# PIC32MZ2048EFM144 register map
Registers are 32-bit, access not given, reset 0x0 unless marked. A register's access mark holds for its fields unless they carry their own. Offsets are from the block's base; [hi:lo] are bit positions; {n}, {i} and the like mark numbered series; 'fields as' and 'values as' point back to an identical list.

## PCACHE — PCACHE peripheral
Base 0xBF8E0000
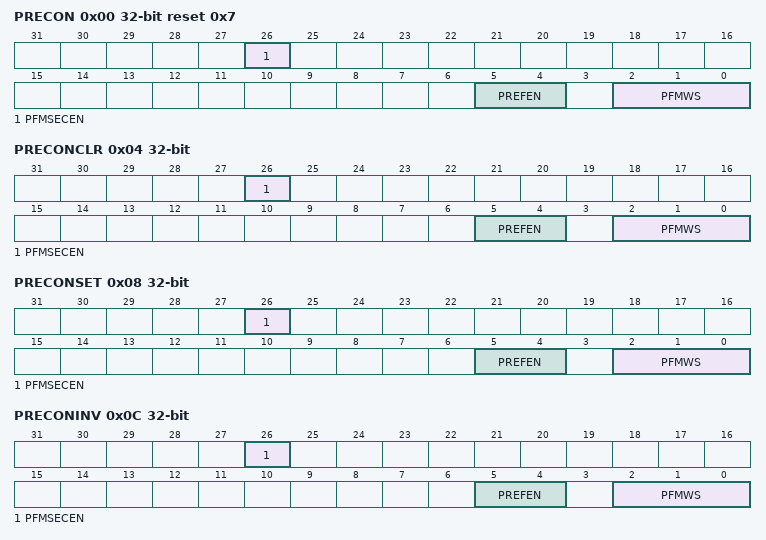
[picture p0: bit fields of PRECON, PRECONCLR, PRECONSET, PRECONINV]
0x00 PRECON reset 0x7
  [26] PFMSECEN, [5:4] PREFEN, [2:0] PFMWS
0x04 PRECONCLR
  [26] PFMSECEN, [5:4] PREFEN, [2:0] PFMWS
0x08 PRECONSET
  [26] PFMSECEN, [5:4] PREFEN, [2:0] PFMWS
0x0C PRECONINV
  [26] PFMSECEN, [5:4] PREFEN, [2:0] PFMWS
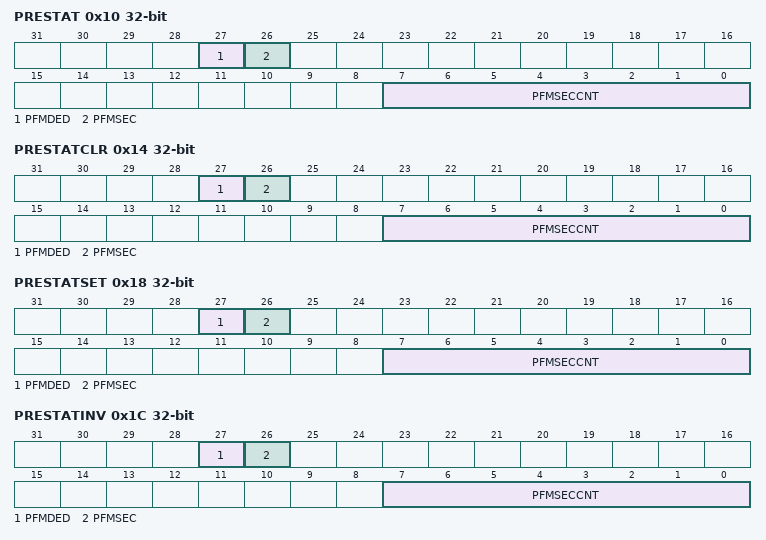
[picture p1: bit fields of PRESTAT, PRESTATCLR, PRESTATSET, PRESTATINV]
0x10 PRESTAT
  [27] PFMDED, [26] PFMSEC, [7:0] PFMSECCNT
0x14 PRESTATCLR
  [27] PFMDED, [26] PFMSEC, [7:0] PFMSECCNT
0x18 PRESTATSET
  [27] PFMDED, [26] PFMSEC, [7:0] PFMSECCNT
0x1C PRESTATINV
  [27] PFMDED, [26] PFMSEC, [7:0] PFMSECCNT

## EBI — EBI peripheral
Base 0xBF8E1014
{0x0+4i} EBICS{i} (i=0..3)
  [31:16] CSADDR
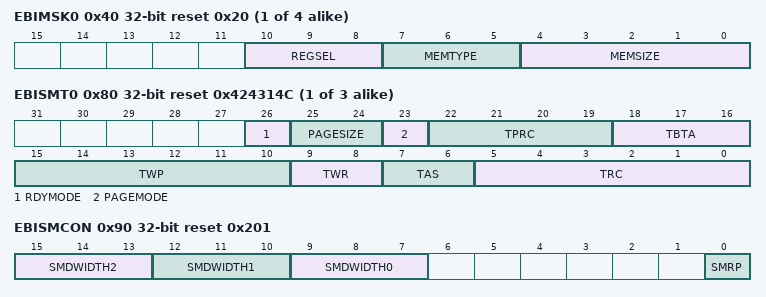
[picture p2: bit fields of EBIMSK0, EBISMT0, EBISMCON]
{0x40+4i} EBIMSK{i} reset 0x20 (i=0..3)
  [10:8] REGSEL, [7:5] MEMTYPE, [4:0] MEMSIZE
{0x80+4i} EBISMT{i} reset 0x424314C (i=0..2)
  [26] RDYMODE, [25:24] PAGESIZE, [23] PAGEMODE, [22:19] TPRC, [18:16] TBTA, [15:10] TWP, [9:8] TWR, [7:6] TAS, [5:0] TRC
0x8C EBIFTRPD reset 0x201
  [31:0] TRPD
0x90 EBISMCON reset 0x201
  [15:13] SMDWIDTH2, [12:10] SMDWIDTH1, [9:7] SMDWIDTH0, [0] SMRP

## SQI1 — SQI1 peripheral
Base 0xBF8E2000
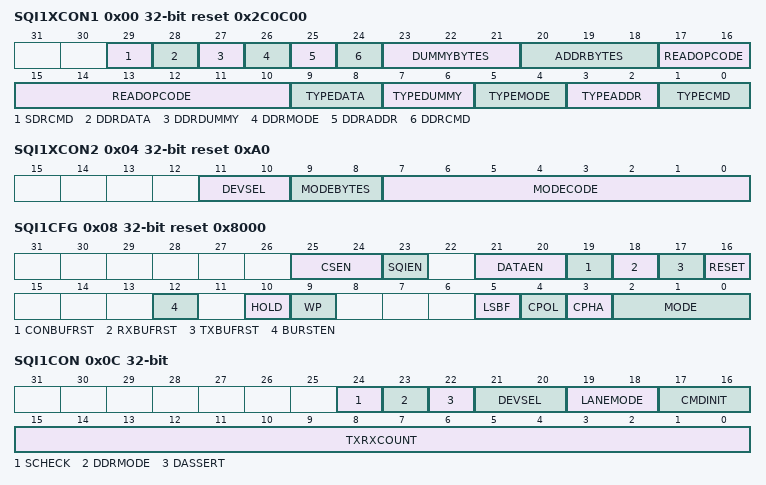
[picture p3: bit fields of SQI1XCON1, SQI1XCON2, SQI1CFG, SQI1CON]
0x00 SQI1XCON1 reset 0x2C0C00
  [29] SDRCMD, [28] DDRDATA, [27] DDRDUMMY, [26] DDRMODE, [25] DDRADDR, [24] DDRCMD, [23:21] DUMMYBYTES, [20:18] ADDRBYTES, [17:10] READOPCODE, [9:8] TYPEDATA, [7:6] TYPEDUMMY, [5:4] TYPEMODE, [3:2] TYPEADDR, [1:0] TYPECMD
0x04 SQI1XCON2 reset 0xA0
  [11:10] DEVSEL, [9:8] MODEBYTES, [7:0] MODECODE
0x08 SQI1CFG reset 0x8000
  [25:24] CSEN, [23] SQIEN, [21:20] DATAEN, [19] CONBUFRST, [18] RXBUFRST, [17] TXBUFRST, [16] RESET, [12] BURSTEN, [10] HOLD, [9] WP, [5] LSBF, [4] CPOL, [3] CPHA, [2:0] MODE
0x0C SQI1CON
  [24] SCHECK, [23] DDRMODE, [22] DASSERT, [21:20] DEVSEL, [19:18] LANEMODE, [17:16] CMDINIT, [15:0] TXRXCOUNT
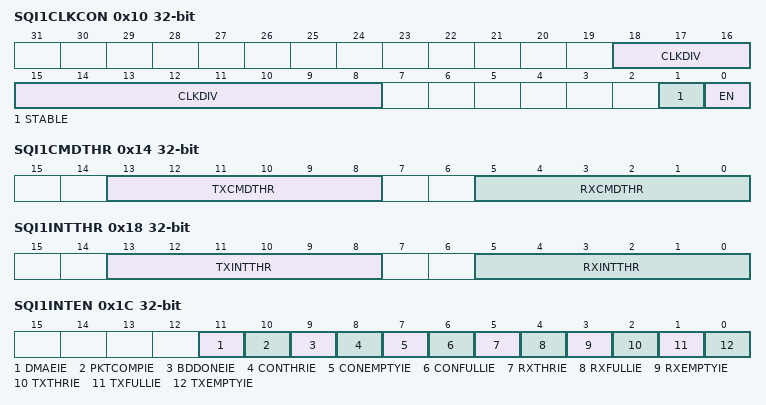
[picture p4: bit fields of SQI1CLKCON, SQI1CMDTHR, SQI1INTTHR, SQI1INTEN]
0x10 SQI1CLKCON
  [18:8] CLKDIV, [1] STABLE, [0] EN
0x14 SQI1CMDTHR
  [13:8] TXCMDTHR, [5:0] RXCMDTHR
0x18 SQI1INTTHR
  [13:8] TXINTTHR, [5:0] RXINTTHR
0x1C SQI1INTEN
  [11] DMAEIE, [10] PKTCOMPIE, [9] BDDONEIE, [8] CONTHRIE, [7] CONEMPTYIE, [6] CONFULLIE, [5] RXTHRIE, [4] RXFULLIE, [3] RXEMPTYIE, [2] TXTHRIE, [1] TXFULLIE, [0] TXEMPTYIE
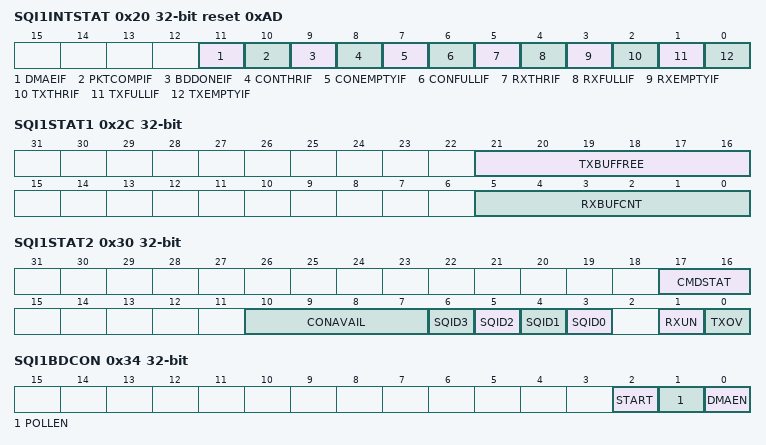
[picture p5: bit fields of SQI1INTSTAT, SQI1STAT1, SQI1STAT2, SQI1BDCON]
0x20 SQI1INTSTAT reset 0xAD
  [11] DMAEIF, [10] PKTCOMPIF, [9] BDDONEIF, [8] CONTHRIF, [7] CONEMPTYIF, [6] CONFULLIF, [5] RXTHRIF, [4] RXFULLIF, [3] RXEMPTYIF, [2] TXTHRIF, [1] TXFULLIF, [0] TXEMPTYIF
0x24 SQI1TXDATA
  [31:0] TXDATA
0x28 SQI1RXDATA
  [31:0] RXDATA
0x2C SQI1STAT1
  [21:16] TXBUFFREE, [5:0] RXBUFCNT
0x30 SQI1STAT2
  [17:16] CMDSTAT, [10:7] CONAVAIL, [n+3] SQID{n} (n=0..3), [1] RXUN, [0] TXOV
0x34 SQI1BDCON
  [2] START, [1] POLLEN, [0] DMAEN
0x38 SQI1BDCURADD
  [31:0] BDCURRADDR
0x40 SQI1BDBASEADD
  [31:0] BDADDR
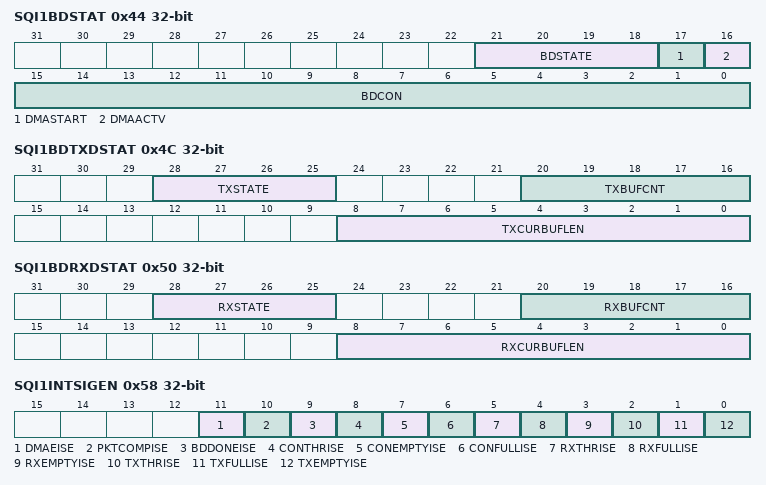
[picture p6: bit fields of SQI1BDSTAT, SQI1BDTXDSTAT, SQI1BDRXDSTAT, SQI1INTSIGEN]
0x44 SQI1BDSTAT
  [21:18] BDSTATE, [17] DMASTART, [16] DMAACTV, [15:0] BDCON
0x48 SQI1BDPOLLCON
  [15:0] POLLCON
0x4C SQI1BDTXDSTAT
  [28:25] TXSTATE, [20:16] TXBUFCNT, [8:0] TXCURBUFLEN
0x50 SQI1BDRXDSTAT
  [28:25] RXSTATE, [20:16] RXBUFCNT, [8:0] RXCURBUFLEN
0x54 SQI1THR
  [3:0] THRES
0x58 SQI1INTSIGEN
  [11] DMAEISE, [10] PKTCOMPISE, [9] BDDONEISE, [8] CONTHRISE, [7] CONEMPTYISE, [6] CONFULLISE, [5] RXTHRISE, [4] RXFULLISE, [3] RXEMPTYISE, [2] TXTHRISE, [1] TXFULLISE, [0] TXEMPTYISE
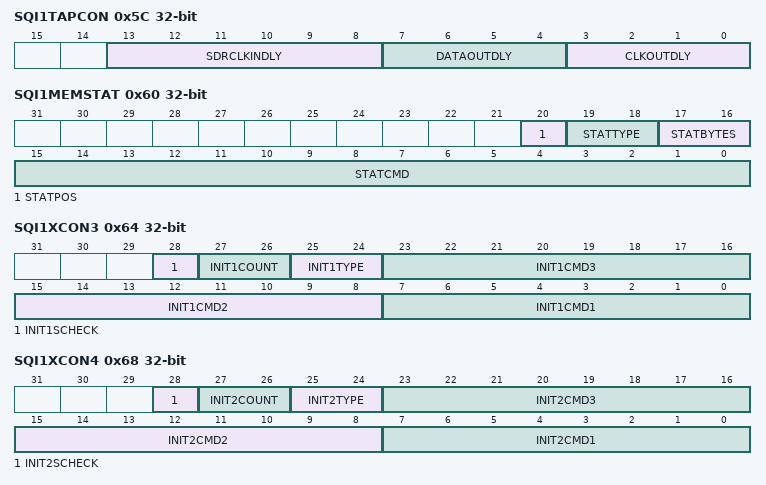
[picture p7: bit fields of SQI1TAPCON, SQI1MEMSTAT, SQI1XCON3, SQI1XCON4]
0x5C SQI1TAPCON
  [13:8] SDRCLKINDLY, [7:4] DATAOUTDLY, [3:0] CLKOUTDLY
0x60 SQI1MEMSTAT
  [20] STATPOS, [19:18] STATTYPE, [17:16] STATBYTES, [15:0] STATCMD
0x64 SQI1XCON3
  [28] INIT1SCHECK, [27:26] INIT1COUNT, [25:24] INIT1TYPE, [23:16] INIT1CMD3, [15:8] INIT1CMD2, [7:0] INIT1CMD1
0x68 SQI1XCON4
  [28] INIT2SCHECK, [27:26] INIT2COUNT, [25:24] INIT2TYPE, [23:16] INIT2CMD3, [15:8] INIT2CMD2, [7:0] INIT2CMD1

## USB — USB peripheral
Base 0xBF8E3000
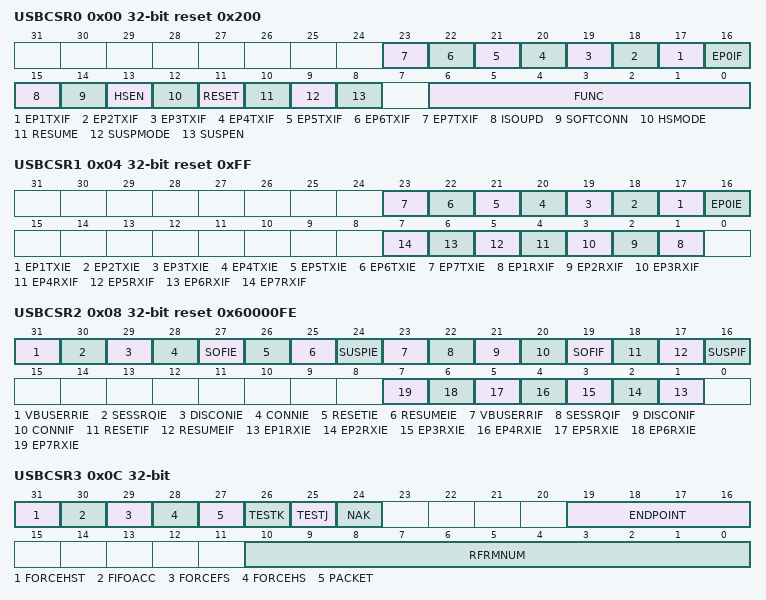
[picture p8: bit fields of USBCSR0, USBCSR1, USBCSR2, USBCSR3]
0x00 USBCSR0 reset 0x200
  [n+16] EP{n}TXIF (n=1..7), [16] EP0IF, [15] ISOUPD, [14] SOFTCONN, [13] HSEN, [12] HSMODE, [11] RESET, [10] RESUME, [9] SUSPMODE, [8] SUSPEN, [6:0] FUNC
0x04 USBCSR1 reset 0xFF
  [n+16] EP{n}TXIE (n=1..7), [16] EP0IE, [n] EP{n}RXIF (n=1..7)
0x08 USBCSR2 reset 0x60000FE
  [31] VBUSERRIE, [30] SESSRQIE, [29] DISCONIE, [28] CONNIE, [27] SOFIE, [26] RESETIE, [25] RESUMEIE, [24] SUSPIE, [23] VBUSERRIF, [22] SESSRQIF, [21] DISCONIF, [20] CONNIF, [19] SOFIF, [18] RESETIF, [17] RESUMEIF, [16] SUSPIF, [n] EP{n}RXIE (n=1..7)
0x0C USBCSR3
  [31] FORCEHST, [30] FIFOACC, [29] FORCEFS, [28] FORCEHS, [27] PACKET, [26] TESTK, [25] TESTJ, [24] NAK, [19:16] ENDPOINT, [10:0] RFRMNUM
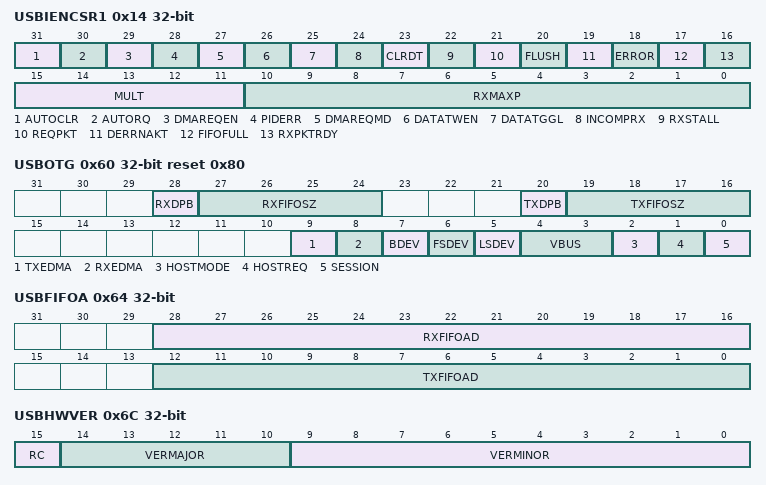
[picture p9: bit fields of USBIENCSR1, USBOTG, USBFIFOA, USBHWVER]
0x14 USBIENCSR1
  [31] AUTOCLR, [30] AUTORQ, [29] DMAREQEN, [28] PIDERR, [27] DMAREQMD, [26] DATATWEN, [25] DATATGGL, [24] INCOMPRX, [23] CLRDT, [22] RXSTALL, [21] REQPKT, [20] FLUSH, [19] DERRNAKT, [18] ERROR, [17] FIFOFULL, [16] RXPKTRDY, [15:11] MULT, [10:0] RXMAXP
{0x20+4i} USBFIFO{i} (i=0..7)
  [31:0] DATA
0x60 USBOTG reset 0x80
  [28] RXDPB, [27:24] RXFIFOSZ, [20] TXDPB, [19:16] TXFIFOSZ, [9] TXEDMA, [8] RXEDMA, [7] BDEV, [6] FSDEV, [5] LSDEV, [4:3] VBUS, [2] HOSTMODE, [1] HOSTREQ, [0] SESSION
0x64 USBFIFOA
  [28:16] RXFIFOAD, [12:0] TXFIFOAD
0x6C USBHWVER
  [15] RC, [14:10] VERMAJOR, [9:0] VERMINOR
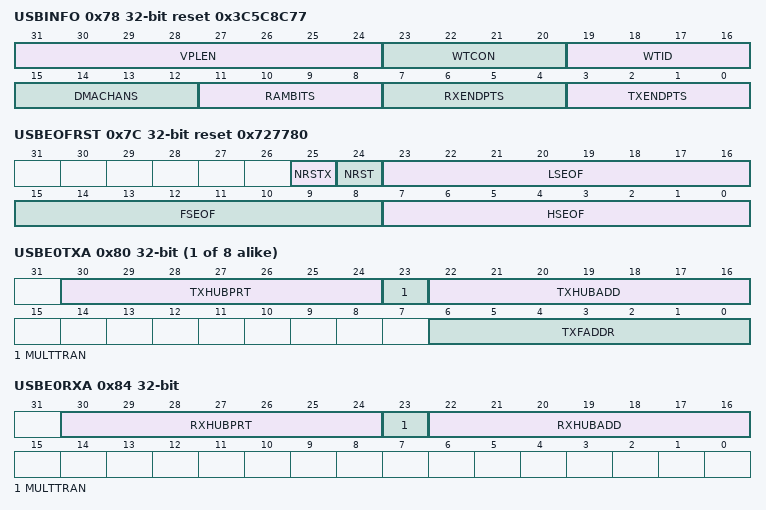
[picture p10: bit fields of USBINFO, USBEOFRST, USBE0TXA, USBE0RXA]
0x78 USBINFO reset 0x3C5C8C77
  [31:24] VPLEN, [23:20] WTCON, [19:16] WTID, [15:12] DMACHANS, [11:8] RAMBITS, [7:4] RXENDPTS, [3:0] TXENDPTS
0x7C USBEOFRST reset 0x727780
  [25] NRSTX, [24] NRST, [23:16] LSEOF, [15:8] FSEOF, [7:0] HSEOF
{0x80+8i} USBE{i}TXA (i=0..7)
  [30:24] TXHUBPRT, [23] MULTTRAN, [22:16] TXHUBADD, [6:0] TXFADDR
0x84 USBE0RXA
  [30:24] RXHUBPRT, [23] MULTTRAN, [22:16] RXHUBADD
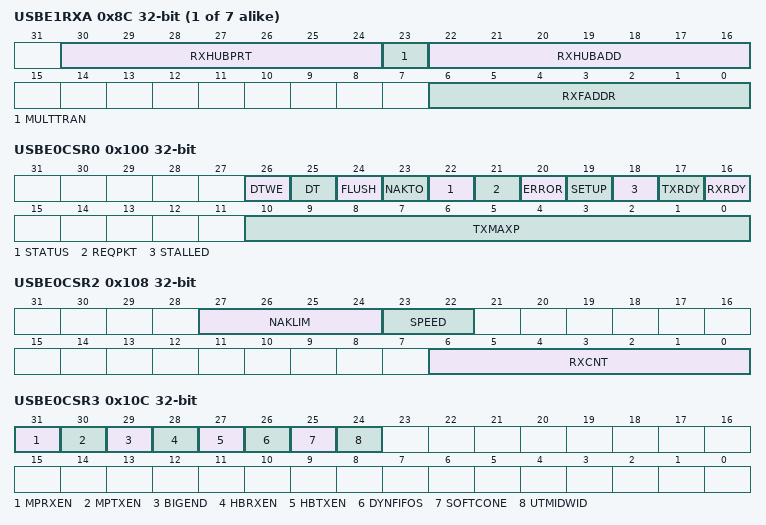
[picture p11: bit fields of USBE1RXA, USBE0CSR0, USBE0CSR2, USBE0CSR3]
{0x84+8i} USBE{i}RXA (i=1..7)
  [30:24] RXHUBPRT, [23] MULTTRAN, [22:16] RXHUBADD, [6:0] RXFADDR
0x100 USBE0CSR0
  [26] DTWE, [25] DT, [24] FLUSH, [23] NAKTO, [22] STATUS, [21] REQPKT, [20] ERROR, [19] SETUP, [18] STALLED, [17] TXRDY, [16] RXRDY, [10:0] TXMAXP
0x108 USBE0CSR2
  [27:24] NAKLIM, [23:22] SPEED, [6:0] RXCNT
0x10C USBE0CSR3
  [31] MPRXEN, [30] MPTXEN, [29] BIGEND, [28] HBRXEN, [27] HBTXEN, [26] DYNFIFOS, [25] SOFTCONE, [24] UTMIDWID
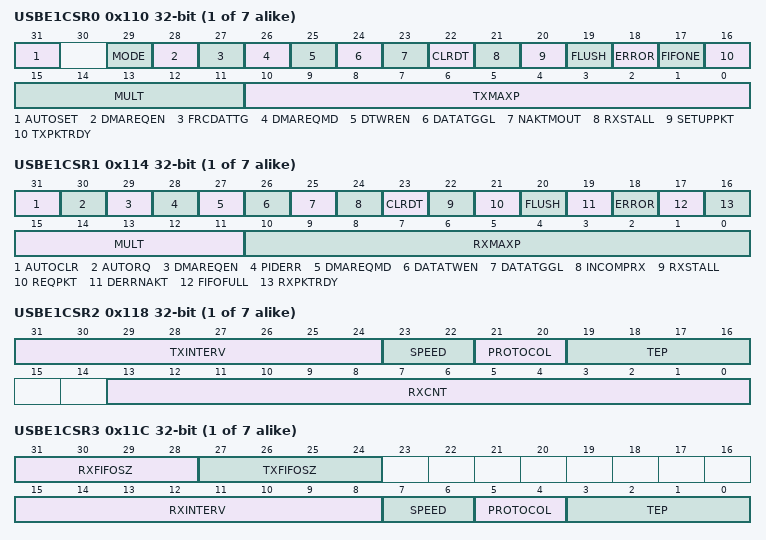
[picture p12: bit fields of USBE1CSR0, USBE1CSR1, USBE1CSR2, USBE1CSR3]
{0x100+0x10*i} USBE{i}CSR0 (i=1..7)
  [31] AUTOSET, [29] MODE, [28] DMAREQEN, [27] FRCDATTG, [26] DMAREQMD, [25] DTWREN, [24] DATATGGL, [23] NAKTMOUT, [22] CLRDT, [21] RXSTALL, [20] SETUPPKT, [19] FLUSH, [18] ERROR, [17] FIFONE, [16] TXPKTRDY, [15:11] MULT, [10:0] TXMAXP
{0x104+0x10*i} USBE{i}CSR1 (i=1..7)
  fields as USBIENCSR1
{0x108+0x10*i} USBE{i}CSR2 (i=1..7)
  [31:24] TXINTERV, [23:22] SPEED, [21:20] PROTOCOL, [19:16] TEP, [13:0] RXCNT
{0x10C+0x10*i} USBE{i}CSR3 (i=1..7)
  [31:28] RXFIFOSZ, [27:24] TXFIFOSZ, [15:8] RXINTERV, [7:6] SPEED, [5:4] PROTOCOL, [3:0] TEP
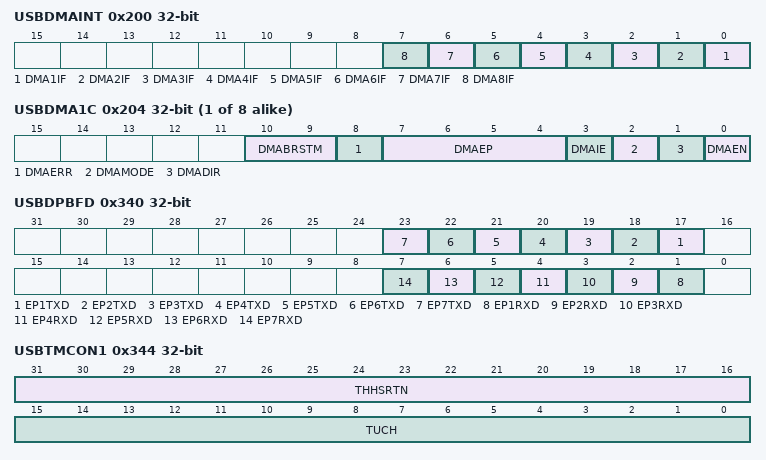
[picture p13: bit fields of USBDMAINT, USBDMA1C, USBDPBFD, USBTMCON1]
0x200 USBDMAINT
  [n-1] DMA{n}IF (n=1..8)
{0x1F4+0x10*i} USBDMA{i}C (i=1..8)
  [10:9] DMABRSTM, [8] DMAERR, [7:4] DMAEP, [3] DMAIE, [2] DMAMODE, [1] DMADIR, [0] DMAEN
{0x1F8+0x10*i} USBDMA{i}A (i=1..8)
  [31:0] DMAADDR
{0x1FC+0x10*i} USBDMA{i}N (i=1..8)
  [31:0] DMACOUNT
{0x300+4i} USBE{i}RPC (i=1..7)
  [15:0] RQPKTCNT
0x340 USBDPBFD
  [n+16] EP{n}TXD (n=1..7), [n] EP{n}RXD (n=1..7)
0x344 USBTMCON1
  [31:16] THHSRTN, [15:0] TUCH
0x348 USBTMCON2
  [3:0] THSBT
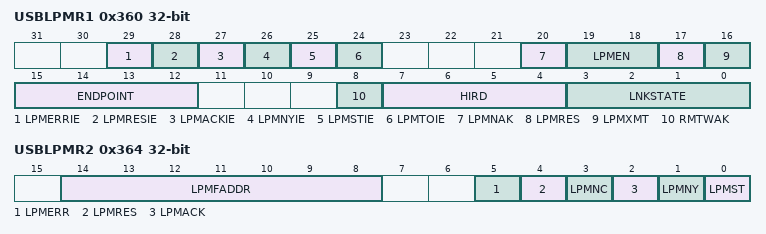
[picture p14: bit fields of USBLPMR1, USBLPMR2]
0x360 USBLPMR1
  [29] LPMERRIE, [28] LPMRESIE, [27] LPMACKIE, [26] LPMNYIE, [25] LPMSTIE, [24] LPMTOIE, [20] LPMNAK, [19:18] LPMEN, [17] LPMRES, [16] LPMXMT, [15:12] ENDPOINT, [8] RMTWAK, [7:4] HIRD, [3:0] LNKSTATE
0x364 USBLPMR2
  [14:8] LPMFADDR, [5] LPMERR, [4] LPMRES, [3] LPMNC, [2] LPMACK, [1] LPMNY, [0] LPMST

## CRYPTO — CRYPTO peripheral
Base 0xBF8E5000
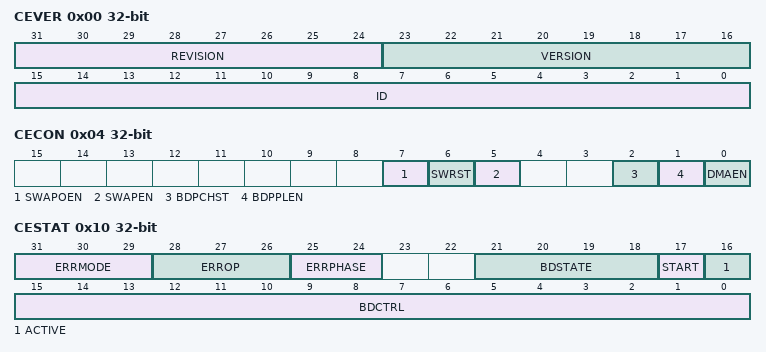
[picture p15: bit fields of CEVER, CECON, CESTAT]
0x00 CEVER
  [31:24] REVISION, [23:16] VERSION, [15:0] ID
0x04 CECON
  [7] SWAPOEN, [6] SWRST, [5] SWAPEN, [2] BDPCHST, [1] BDPPLEN, [0] DMAEN
0x08 CEBDADDR
  [31:0] BDPADDR
0x0C CEBDPADDR
  [31:0] BASEADDR
0x10 CESTAT
  [31:29] ERRMODE, [28:26] ERROP, [25:24] ERRPHASE, [21:18] BDSTATE, [17] START, [16] ACTIVE, [15:0] BDCTRL
0x14 CEINTSRC
  [3] AREIF, [2] PKTIF, [1] CBDIF, [0] PENDIF
0x18 CEINTEN
  [3] AREIE, [2] PKTIE, [1] CBDIE, [0] PENDIE
0x1C CEPOLLCON
  [15:0] BDPPLCON
0x20 CEHDLEN
  [7:0] HDRLEN
0x24 CETRLLEN
  [7:0] TRLRLEN

## RNG — RNG peripheral
Base 0xBF8E6000
0x00 RNGVER
  [31:16] ID, [15:7] VERSION, [6:0] REVISION
0x04 RNGCON reset 0x40
  [12] LOAD, [11] TRNGMODE, [10] CONT, [9] PRNGEN, [8] TRNGEN, [7:0] PLEN
0x08 RNGPOLY1 reset 0xFFFF0000
  [31:0] POLY
0x0C RNGPOLY2 reset 0xFFFF0000
  [31:0] POLY
0x10 RNGNUMGEN1 reset 0xFFFFFFFF
  [31:0] RNG
0x14 RNGNUMGEN2 reset 0xFFFFFFFF
  [31:0] RNG
0x18 RNGSEED1
  [31:0] SEED
0x1C RNGSEED2
  [31:0] SEED
0x20 RNGCNT
  [6:0] RCNT

## SB — SB peripheral
Base 0xBF8F0510
0x00 SBFLAG
  [n] T{n}PGV (n=0..13)
{0x7B10+0x400*i} SBT{i}ELOG1 (i=0..13)
  [31] MULTI, [27:24] CODE, [15:8] INITID, [7:4] REGION, [2:0] CMD
{0x7B14+0x400*i} SBT{i}ELOG2 (i=0..13)
  [1:0] GROUP
{0x7B18+0x400*i} SBT{i}ECON (i=0..13)
  [24] ERRP
{0x7B20+0x400*i} SBT{i}ECLRS (i=0..13)
  [0] CLEAR
{0x7B28+0x400*i} SBT{i}ECLRM (i=0..13)
  [0] CLEAR
{0x7B30+0x400*i} SBT{i}REG0 (i=0..13)
  [31:10] BASE, [9] PRI, [7:3] SIZE
{0x7B40+0x400*i} SBT{i}RD0 reset 0xF (i=0..13)
  [n] GROUP{n} (n=0..3)
{0x7B48+0x400*i} SBT{i}WR0 reset 0xF (i=0..13)
  [n] GROUP{n} (n=0..3)
0x7B50 SBT0REG1
  [31:10] BASE, [9] PRI, [7:3] SIZE
0x7B60 SBT0RD1 reset 0xF
  [n] GROUP{n} (n=0..3)
0x7B68 SBT0WR1 reset 0xF
  [n] GROUP{n} (n=0..3)
{0x7B70+0x400*i} SBT{i}REG2 (i=1..5)
  [31:10] BASE, [9] PRI, [7:3] SIZE
{0x7B80+0x400*i} SBT{i}RD2 reset 0xF (i=1..5)
  [n] GROUP{n} (n=0..3)
{0x7B88+0x400*i} SBT{i}WR2 reset 0xF (i=1..5)
  [n] GROUP{n} (n=0..3)
0x7F90 SBT1REG3
  [31:10] BASE, [9] PRI, [7:3] SIZE
0x7FA0 SBT1RD3 reset 0xF
  [n] GROUP{n} (n=0..3)
0x7FA8 SBT1WR3 reset 0xF
  [n] GROUP{n} (n=0..3)
0x7FB0 SBT1REG4
  [31:10] BASE, [9] PRI, [7:3] SIZE
0x7FC0 SBT1RD4 reset 0xF
  [n] GROUP{n} (n=0..3)
0x7FC8 SBT1WR4 reset 0xF
  [n] GROUP{n} (n=0..3)
0x7FD0 SBT1REG5
  [31:10] BASE, [9] PRI, [7:3] SIZE
0x7FE0 SBT1RD5 reset 0xF
  [n] GROUP{n} (n=0..3)
0x7FE8 SBT1WR5 reset 0xF
  [n] GROUP{n} (n=0..3)
0x7FF0 SBT1REG6
  [31:10] BASE, [9] PRI, [7:3] SIZE
0x8000 SBT1RD6 reset 0xF
  [n] GROUP{n} (n=0..3)
0x8008 SBT1WR6 reset 0xF
  [n] GROUP{n} (n=0..3)
0x8010 SBT1REG7
  [31:10] BASE, [9] PRI, [7:3] SIZE
0x8020 SBT1RD7 reset 0xF
  [n] GROUP{n} (n=0..3)
0x8028 SBT1WR7 reset 0xF
  [n] GROUP{n} (n=0..3)
0x8030 SBT1REG8
  [31:10] BASE, [9] PRI, [7:3] SIZE
0x8040 SBT1RD8 reset 0xF
  [n] GROUP{n} (n=0..3)
0x8048 SBT1WR8 reset 0xF
  [n] GROUP{n} (n=0..3)
0x8350 SBT2REG1
  [31:10] BASE, [9] PRI, [7:3] SIZE
0x8360 SBT2RD1 reset 0xF
  [n] GROUP{n} (n=0..3)
0x8368 SBT2WR1 reset 0xF
  [n] GROUP{n} (n=0..3)
0x8750 SBT3REG1
  [31:10] BASE, [9] PRI, [7:3] SIZE
0x8760 SBT3RD1 reset 0xF
  [n] GROUP{n} (n=0..3)
0x8768 SBT3WR1 reset 0xF
  [n] GROUP{n} (n=0..3)
{0x7B50+0x400*i} SBT{i}REG1 (i=5..9)
  [31:10] BASE, [9] PRI, [7:3] SIZE
{0x7B60+0x400*i} SBT{i}RD1 reset 0xF (i=5..9)
  [n] GROUP{n} (n=0..3)
{0x7B68+0x400*i} SBT{i}WR1 reset 0xF (i=5..9)
  [n] GROUP{n} (n=0..3)
0xA750 SBT11REG1
  [31:10] BASE, [9] PRI, [7:3] SIZE
0xA760 SBT11RD1 reset 0xF
  [n] GROUP{n} (n=0..3)
0xA768 SBT11WR1 reset 0xF
  [n] GROUP{n} (n=0..3)
